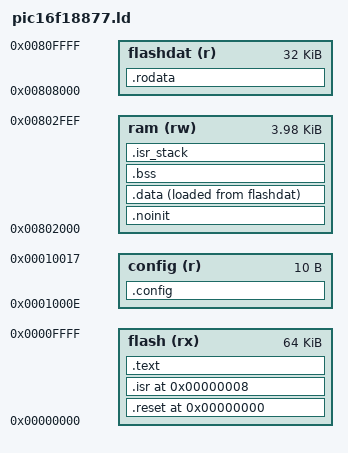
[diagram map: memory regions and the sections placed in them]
/* Linker script for the PIC16F18877.
 * Generated by tools/devdb/gen_toolchain.py from Microchip.PIC16F1xxxx_DFP 1.32.471,
 * edc/PIC16F18877.PIC. Do not edit.
 *
 * Address spaces:
 *   0x000000 up   program memory, as byte addresses (two per 14-bit word)
 *   0x802000 up   RAM in the linear view the FSR registers use
 *   0x808000 up   flash read as data through an FSR, one byte per word
 */
/* Library variant: banks64 */
OUTPUT_FORMAT("elf32-pic16f1")
ENTRY(_start)

MEMORY
{
  flash    (rx) : ORIGIN = 0x000000, LENGTH = 0x10000
  ram      (rw) : ORIGIN = 0x802000, LENGTH = 4080
  flashdat (r)  : ORIGIN = 0x808000, LENGTH = 0x8000
  config   (r)  : ORIGIN = 0x1000e, LENGTH = 10
}


/* Bytes of stack for the interrupt handler, if there is one. */
PROVIDE(__isr_stack_size = 32);
/* Bytes kept for the main stack when a heap is in use. */
PROVIDE(__stack_size = 256);

SECTIONS
{
  /* Reset vector at word 0, interrupt vector at word 4. */
  .reset 0x0 : { KEEP(*(.reset)) } > flash
  .isr 0x8 : { KEEP(*(.isr)) } > flash
  /* Startup code first, in the order of its pieces (see crt0.S). */
  .text :
  {
    KEEP(*(.init0)) KEEP(*(.init4)) KEEP(*(.init5)) KEEP(*(.init6))
    KEEP(*(.init9))
    *(.text .text.*)
  } > flash
  __text_end = .;

  /* Constants follow the code in flash. Their addresses are in the FSR
   * view: 0x8000 plus the word address, one byte in each word. */
  .rodata (ORIGIN(flashdat) + (__text_end + 1) / 2) :
  {
    *(.rodata .rodata.*)
  } > flashdat

  /* Variables that have a fixed address in place of a stack frame, and
   * the stack pointer cell. Like stack variables they have no initial
   * value, so startup skips them. They come first in RAM, the runtime
   * library's before the rest: that library is built once, with the bank
   * selection of a 32-bank device, and must find its variables in the
   * first 32 banks of a larger one too. */
  .noinit (NOLOAD) :
  {
    /* The stack pointer cell comes first of all, at a fixed address:
     * debug information that cannot hold a relocation names it. */
    *(.noinit.__sp)
    *libpicrt*.a:*(.noinit .noinit.*)
    *(.noinit .noinit.*)
  } > ram

  .data :
  {
    __data_start = .;
    *(.data .data.*)
    __data_end = .;
  } > ram AT> flashdat
  __data_load_start = LOADADDR(.data);
  __data_size = SIZEOF(.data);

  .bss (NOLOAD) :
  {
    __bss_start = .;
    *(.bss .bss.*)
    *(COMMON)
    __bss_end = .;
  } > ram
  __bss_size = SIZEOF(.bss);

  .isr_stack (NOLOAD) :
  {
    . += (SIZEOF(.isr) > 0) ? __isr_stack_size : 0;
    __isr_stack_top = .;
  } > ram

  /* The main stack grows down from the end of RAM. */
  __stack_top = ORIGIN(ram) + LENGTH(ram);

  /* malloc, if the program uses it, takes the RAM between the data and the
   * space set aside for the stack. Nothing enforces the boundary. */
  __heap_start = .;
  __heap_end = __stack_top - __stack_size;

  .config : { KEEP(*(.config)) } > config

  __flash_words_used = (__text_end + 1) / 2 + SIZEOF(.rodata) + SIZEOF(.data);
  ASSERT(__flash_words_used <= 32768, "program does not fit in flash")

  /* Code compiled with -mcmodel=small never sets PCLATH, which is right
   * only if all code lies in the first page. Such code refers to
   * __pic16f1_one_page. */
  PROVIDE(__pic16f1_one_page = 1);
  ASSERT(DEFINED(__pic16f1_one_page) ? __text_end <= 0x1000 : 1,
         "code compiled with -mcmodel=small, but the program is larger than one page (2K words)")

  /DISCARD/ : { *(.note.GNU-stack) *(.comment) *(.eh_frame) *(.llvm_addrsig) }
}
